# MESSIBLE register map
Vendor: litex
Registers are 8-bit, read-write, reset 0x0 unless marked. A register's access mark holds for its fields unless they carry their own. Offsets are from the block's base; lines under a group give offsets from that group; [hi:lo] are bit positions; {n}, {i} and the like mark numbered series; 'fields as' and 'values as' point back to an identical list; <NAME> marks a mode.

## Memory map
0xE0000000 CTRL size 0x24
0xE0001000 UART_PHY size 0x10
0xE0001800 UART size 0x18
0xE0002800 TIMER0 size 0x44
0xE0004800 USB size 0x54
0xE0008000 MESSIBLE size 0xC

## Interrupts
0 uart (UART)
2 timer0 (TIMER0)
3 usb (USB)

## CTRL
Base 0xE0000000
0x00 RESET — Write a ``1`` to this register to reset the SoC.
  [0] reset
0x04 SCRATCH3 reset 0x12 — Bits 24-31 of `CTRL_SCRATCH`. Use this register as a scratch space to verify that software read/write accesses to the Wishbone/CSR bus are working correctly. The initial reset value of 0x1234578 can be used to verify endianness.
  [7:0] scratch
0x08 SCRATCH2 reset 0x34 — Bits 16-23 of `CTRL_SCRATCH`.
  [7:0] scratch
0x0C SCRATCH1 reset 0x56 — Bits 8-15 of `CTRL_SCRATCH`.
  [7:0] scratch
0x10 SCRATCH0 reset 0x78 — Bits 0-7 of `CTRL_SCRATCH`.
  [7:0] scratch
0x14 BUS_ERRORS3 ro — Bits 24-31 of `CTRL_BUS_ERRORS`. Total number of Wishbone bus errors (timeouts) since start.
  [7:0] bus_errors
0x18 BUS_ERRORS2 ro — Bits 16-23 of `CTRL_BUS_ERRORS`.
  [7:0] bus_errors
0x1C BUS_ERRORS1 ro — Bits 8-15 of `CTRL_BUS_ERRORS`.
  [7:0] bus_errors
0x20 BUS_ERRORS0 ro — Bits 0-7 of `CTRL_BUS_ERRORS`.
  [7:0] bus_errors

## UART_PHY
Base 0xE0001000
0x00 TUNING_WORD3 reset 0x2 — Bits 24-31 of `UART_PHY_TUNING_WORD`.
  [7:0] tuning_word
0x04 TUNING_WORD2 reset 0x75 — Bits 16-23 of `UART_PHY_TUNING_WORD`.
  [7:0] tuning_word
0x08 TUNING_WORD1 reset 0x25 — Bits 8-15 of `UART_PHY_TUNING_WORD`.
  [7:0] tuning_word
0x0C TUNING_WORD0 reset 0x46 — Bits 0-7 of `UART_PHY_TUNING_WORD`.
  [7:0] tuning_word

## UART
Base 0xE0001800
0x00 RXTX
0x04 TXFULL ro
  [0] txfull
0x08 RXEMPTY ro
  [0] rxempty
0x0C EV_STATUS
  [1:0] status
0x10 EV_PENDING
  [1:0] pending
0x14 EV_ENABLE
  [1:0] enable

## TIMER0
Base 0xE0002800
0x00 LOAD3 — Bits 24-31 of `TIMER0_LOAD`. Load value when Timer is (re-)enabled. In One-Shot mode, the value written to this register specifies the Timer's duration in clock cycles.
  [7:0] load
0x04 LOAD2 — Bits 16-23 of `TIMER0_LOAD`.
  [7:0] load
0x08 LOAD1 — Bits 8-15 of `TIMER0_LOAD`.
  [7:0] load
0x0C LOAD0 — Bits 0-7 of `TIMER0_LOAD`.
  [7:0] load
0x10 RELOAD3 — Bits 24-31 of `TIMER0_RELOAD`. Reload value when Timer reaches ``0``. In Periodic mode, the value written to this register specify the Timer's period in clock cycles.
  [7:0] reload
0x14 RELOAD2 — Bits 16-23 of `TIMER0_RELOAD`.
  [7:0] reload
0x18 RELOAD1 — Bits 8-15 of `TIMER0_RELOAD`.
  [7:0] reload
0x1C RELOAD0 — Bits 0-7 of `TIMER0_RELOAD`.
  [7:0] reload
0x20 EN — Enable flag of the Timer. Set this flag to ``1`` to enable/start the Timer. Set to ``0`` to disable the Timer.
  [0] en
0x24 UPDATE_VALUE — Update trigger for the current countdown value. A write to this register latches the current countdown value to ``value`` register.
  [0] update_value
0x28 VALUE3 ro — Bits 24-31 of `TIMER0_VALUE`. Latched countdown value. This value is updated by writing to ``update_value``.
  [7:0] value
0x2C VALUE2 ro — Bits 16-23 of `TIMER0_VALUE`.
  [7:0] value
0x30 VALUE1 ro — Bits 8-15 of `TIMER0_VALUE`.
  [7:0] value
0x34 VALUE0 ro — Bits 0-7 of `TIMER0_VALUE`.
  [7:0] value
0x38 EV_STATUS
  [0] status
0x3C EV_PENDING
  [0] pending
0x40 EV_ENABLE
  [0] enable

## MESSIBLE
Base 0xE0008000
0x00 IN — Write half of the FIFO to send data out the Messible. Writing to this register advances the write pointer automatically.
0x04 OUT ro — Read half of the FIFO to receive data on the Messible. Reading from this register advances the read pointer automatically.
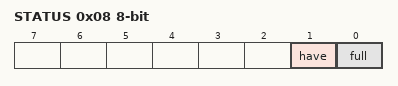
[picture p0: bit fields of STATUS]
0x08 STATUS ro
  [1] have — ``1`` if data can be read from the OUT FIFO.
  [0] full — ``0`` if more data can fit into the IN FIFO.
